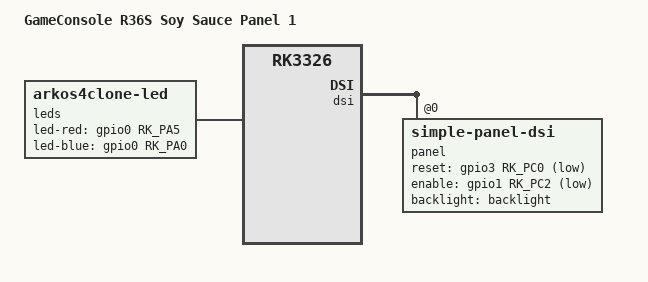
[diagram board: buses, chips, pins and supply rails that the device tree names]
// SPDX-License-Identifier: (GPL-2.0+ OR MIT)
/*
* Copyright (c) 2026 kk&lcdyk
*
* R36S 酱油 Panel 1
*
*/

/dts-v1/;
#include "rk3326-r36s-sauce.dtsi"

/ {
	model = "GameConsole R36S Soy Sauce Panel 1";
	compatible = "rockchip,rk3326-r36s-sauce-panel1-linux", "rockchip,rk3326";

	leds: arkos4clone-leds {
		compatible = "arkos4clone-led";
		
		led-red = <&gpio0 RK_PA5 GPIO_ACTIVE_HIGH>;
		led-blue = <&gpio0 RK_PA0 GPIO_ACTIVE_HIGH>;
	};
};

&dsi {
	status = "okay";
	
	panel@0 {
		compatible = "simple-panel-dsi";
		reg = <0>;
		/* pwm1 backlight */
		backlight = <&backlight>;
		/* LCD reset gpio GPIO3.B7 */
		reset-gpios = <&gpio3 RK_PC0 GPIO_ACTIVE_LOW>;
		/* power-supply-gpio GPIO0.B5  */
		enable-gpios = <&gpio1 RK_PC2 GPIO_ACTIVE_LOW>;
		prepare-delay-ms = <100>;
		reset-delay-ms = <50>;
		init-delay-ms = <20>;
		enable-delay-ms = <200>;
		disable-delay-ms = <50>;
		unprepare-delay-ms = <250>;
		width-mm = <71>;
		height-mm = <71>;
		dsi,flags  = <(MIPI_DSI_MODE_VIDEO |
		MIPI_DSI_MODE_VIDEO_BURST |
		MIPI_DSI_MODE_LPM |
		MIPI_DSI_MODE_EOT_PACKET)>;
		dsi,format = <MIPI_DSI_FMT_RGB888>;
		dsi,lanes = <4>;
		panel-init-sequence = [39 00 04 b9 f1 12 83 39 00 1c ba 33 81 05 f9 0e 0e 20 00 00 00 00 00 00 00 44 25 00 91 0a 00 00 02 4f d1 00 00 37 15 00 02 b8 25 39 00 04 bf 02 11 00 39 00 0b b3 0c 10 0a 50 03 ff 00 00 00 00 39 00 0a c0 73 73 50 50 00 00 08 70 00 15 00 02 bc 46 15 00 02 cc 0b 15 00 02 b4 80 39 00 04 b2 00 13 f0 39 00 0f e3 07 07 0b 0b 03 0b 00 00 00 00 ff 00 c0 10 39 00 0d c1 53 00 1e 1e 77 e1 cc dd 67 77 33 33 39 00 03 b5 10 10 39 00 03 b6 6c 7c 39 00 40 e9 08 00 0e 00 00 b0 b1 11 31 23 28 10 b0 b1 27 08 00 04 02 00 00 00 00 04 02 00 00 00 88 88 ba 60 24 08 88 88 88 88 88 88 88 ba 71 35 18 88 88 88 88 88 00 00 00 01 00 00 00 00 00 00 00 00 00 39 00 3e ea 97 0a 82 02 13 07 00 00 00 00 00 00 80 88 ba 17 53 88 88 88 88 88 88 81 88 ba 06 42 88 88 88 88 88 88 23 10 00 02 80 00 00 00 00 00 00 00 00 00 00 00 00 00 00 00 00 00 00 00 00 00 00 39 00 23 e0 00 07 0b 27 2d 3f 3b 37 05 0a 0b 0f 11 0f 12 12 18 00 07 0b 27 2d 3f 3b 37 05 0a 0b 0f 11 0f 12 12 18 05 96 01 11 05 32 01 29];
		panel-exit-sequence = <0x5140128 0x50a0110>;
		
		display-timings {
			native-mode = <&timing0>;

			// 40.00MHz / (640+120+120+120)×(480+17+5+13) = 1000×515 = 77.67 Hz
			timing0: original {
				clock-frequency = <40000000>;
				hactive = <640>;
				vactive = <480>;
				hback-porch = <120>;
				hfront-porch = <120>;
				vback-porch = <13>;
				vfront-porch = <17>;
				hsync-len = <120>;
				vsync-len = <5>;
				hsync-active = <0>;
				vsync-active = <0>;
				de-active = <0>;
				pixelclk-active = <0>;
			};
			
			// 40.00MHz / (640+218+218+218)×(480+17+5+13) = 1294×515 = 60.02 Hz
			timing1: adjust {
				clock-frequency = <40000000>;
				hactive = <640>;
				vactive = <480>;
				hback-porch = <218>;
				hfront-porch = <218>;
				vback-porch = <13>;
				vfront-porch = <17>;
				hsync-len = <218>;
				vsync-len = <5>;
				hsync-active = <0>;
				vsync-active = <0>;
				de-active = <0>;
				pixelclk-active = <0>;
			};
		};
	};
};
